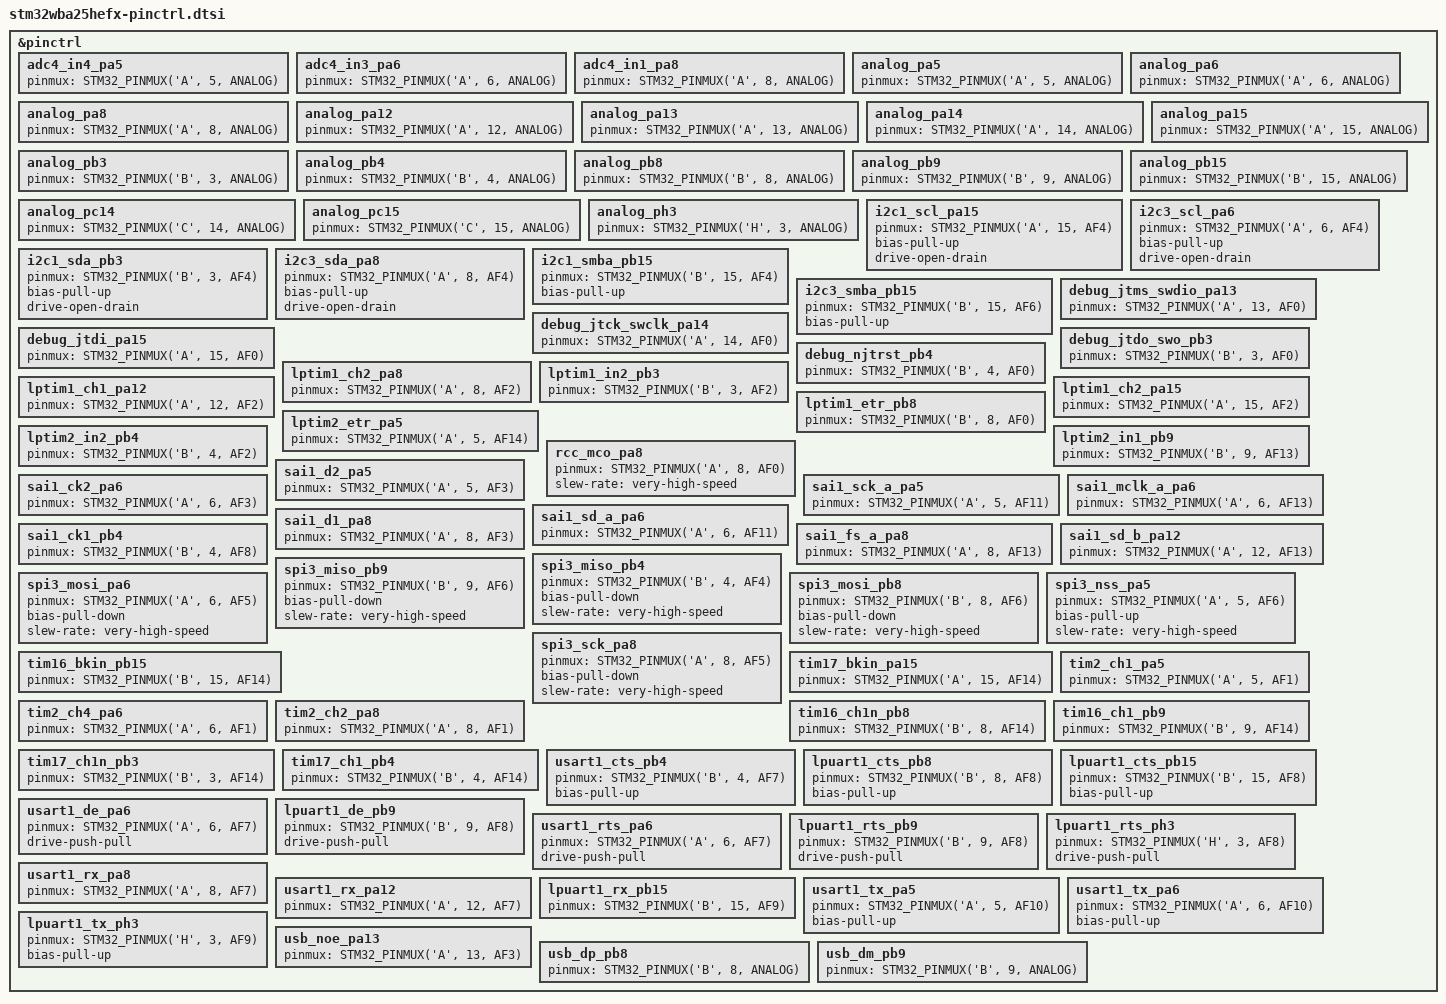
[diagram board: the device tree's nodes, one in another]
/*
 * NOTE: Autogenerated file using genpinctrl.py
 *
 * SPDX-License-Identifier: Apache-2.0
 */

#include <zephyr/dt-bindings/pinctrl/stm32-pinctrl.h>

&pinctrl {

	/* ADC_IN / ADC_INN / ADC_INP */

	/omit-if-no-ref/ adc4_in4_pa5: adc4_in4_pa5 {
		pinmux = <STM32_PINMUX('A', 5, ANALOG)>;
	};

	/omit-if-no-ref/ adc4_in3_pa6: adc4_in3_pa6 {
		pinmux = <STM32_PINMUX('A', 6, ANALOG)>;
	};

	/omit-if-no-ref/ adc4_in1_pa8: adc4_in1_pa8 {
		pinmux = <STM32_PINMUX('A', 8, ANALOG)>;
	};

	/* Analog */

	/omit-if-no-ref/ analog_pa5: analog_pa5 {
		pinmux = <STM32_PINMUX('A', 5, ANALOG)>;
	};

	/omit-if-no-ref/ analog_pa6: analog_pa6 {
		pinmux = <STM32_PINMUX('A', 6, ANALOG)>;
	};

	/omit-if-no-ref/ analog_pa8: analog_pa8 {
		pinmux = <STM32_PINMUX('A', 8, ANALOG)>;
	};

	/omit-if-no-ref/ analog_pa12: analog_pa12 {
		pinmux = <STM32_PINMUX('A', 12, ANALOG)>;
	};

	/omit-if-no-ref/ analog_pa13: analog_pa13 {
		pinmux = <STM32_PINMUX('A', 13, ANALOG)>;
	};

	/omit-if-no-ref/ analog_pa14: analog_pa14 {
		pinmux = <STM32_PINMUX('A', 14, ANALOG)>;
	};

	/omit-if-no-ref/ analog_pa15: analog_pa15 {
		pinmux = <STM32_PINMUX('A', 15, ANALOG)>;
	};

	/omit-if-no-ref/ analog_pb3: analog_pb3 {
		pinmux = <STM32_PINMUX('B', 3, ANALOG)>;
	};

	/omit-if-no-ref/ analog_pb4: analog_pb4 {
		pinmux = <STM32_PINMUX('B', 4, ANALOG)>;
	};

	/omit-if-no-ref/ analog_pb8: analog_pb8 {
		pinmux = <STM32_PINMUX('B', 8, ANALOG)>;
	};

	/omit-if-no-ref/ analog_pb9: analog_pb9 {
		pinmux = <STM32_PINMUX('B', 9, ANALOG)>;
	};

	/omit-if-no-ref/ analog_pb15: analog_pb15 {
		pinmux = <STM32_PINMUX('B', 15, ANALOG)>;
	};

	/omit-if-no-ref/ analog_pc14: analog_pc14 {
		pinmux = <STM32_PINMUX('C', 14, ANALOG)>;
	};

	/omit-if-no-ref/ analog_pc15: analog_pc15 {
		pinmux = <STM32_PINMUX('C', 15, ANALOG)>;
	};

	/omit-if-no-ref/ analog_ph3: analog_ph3 {
		pinmux = <STM32_PINMUX('H', 3, ANALOG)>;
	};

	/* I2C_SCL */

	/omit-if-no-ref/ i2c1_scl_pa15: i2c1_scl_pa15 {
		pinmux = <STM32_PINMUX('A', 15, AF4)>;
		bias-pull-up;
		drive-open-drain;
	};

	/omit-if-no-ref/ i2c3_scl_pa6: i2c3_scl_pa6 {
		pinmux = <STM32_PINMUX('A', 6, AF4)>;
		bias-pull-up;
		drive-open-drain;
	};

	/* I2C_SDA */

	/omit-if-no-ref/ i2c1_sda_pb3: i2c1_sda_pb3 {
		pinmux = <STM32_PINMUX('B', 3, AF4)>;
		bias-pull-up;
		drive-open-drain;
	};

	/omit-if-no-ref/ i2c3_sda_pa8: i2c3_sda_pa8 {
		pinmux = <STM32_PINMUX('A', 8, AF4)>;
		bias-pull-up;
		drive-open-drain;
	};

	/* I2C_SMBA */

	/omit-if-no-ref/ i2c1_smba_pb15: i2c1_smba_pb15 {
		pinmux = <STM32_PINMUX('B', 15, AF4)>;
		bias-pull-up;
	};

	/omit-if-no-ref/ i2c3_smba_pb15: i2c3_smba_pb15 {
		pinmux = <STM32_PINMUX('B', 15, AF6)>;
		bias-pull-up;
	};

	/* JTAG PORT */

	/omit-if-no-ref/ debug_jtms_swdio_pa13: debug_jtms_swdio_pa13 {
		pinmux = <STM32_PINMUX('A', 13, AF0)>;
	};

	/omit-if-no-ref/ debug_jtck_swclk_pa14: debug_jtck_swclk_pa14 {
		pinmux = <STM32_PINMUX('A', 14, AF0)>;
	};

	/omit-if-no-ref/ debug_jtdi_pa15: debug_jtdi_pa15 {
		pinmux = <STM32_PINMUX('A', 15, AF0)>;
	};

	/omit-if-no-ref/ debug_jtdo_swo_pb3: debug_jtdo_swo_pb3 {
		pinmux = <STM32_PINMUX('B', 3, AF0)>;
	};

	/omit-if-no-ref/ debug_njtrst_pb4: debug_njtrst_pb4 {
		pinmux = <STM32_PINMUX('B', 4, AF0)>;
	};

	/* LPTIM */

	/omit-if-no-ref/ lptim1_ch2_pa8: lptim1_ch2_pa8 {
		pinmux = <STM32_PINMUX('A', 8, AF2)>;
	};

	/omit-if-no-ref/ lptim1_ch1_pa12: lptim1_ch1_pa12 {
		pinmux = <STM32_PINMUX('A', 12, AF2)>;
	};

	/omit-if-no-ref/ lptim1_ch2_pa15: lptim1_ch2_pa15 {
		pinmux = <STM32_PINMUX('A', 15, AF2)>;
	};

	/omit-if-no-ref/ lptim1_in2_pb3: lptim1_in2_pb3 {
		pinmux = <STM32_PINMUX('B', 3, AF2)>;
	};

	/omit-if-no-ref/ lptim1_etr_pb8: lptim1_etr_pb8 {
		pinmux = <STM32_PINMUX('B', 8, AF0)>;
	};

	/omit-if-no-ref/ lptim2_etr_pa5: lptim2_etr_pa5 {
		pinmux = <STM32_PINMUX('A', 5, AF14)>;
	};

	/omit-if-no-ref/ lptim2_in2_pb4: lptim2_in2_pb4 {
		pinmux = <STM32_PINMUX('B', 4, AF2)>;
	};

	/omit-if-no-ref/ lptim2_in1_pb9: lptim2_in1_pb9 {
		pinmux = <STM32_PINMUX('B', 9, AF13)>;
	};

	/* RCC_MCO */

	/omit-if-no-ref/ rcc_mco_pa8: rcc_mco_pa8 {
		pinmux = <STM32_PINMUX('A', 8, AF0)>;
		slew-rate = "very-high-speed";
	};

	/* SAI */

	/omit-if-no-ref/ sai1_d2_pa5: sai1_d2_pa5 {
		pinmux = <STM32_PINMUX('A', 5, AF3)>;
	};

	/omit-if-no-ref/ sai1_sck_a_pa5: sai1_sck_a_pa5 {
		pinmux = <STM32_PINMUX('A', 5, AF11)>;
	};

	/omit-if-no-ref/ sai1_ck2_pa6: sai1_ck2_pa6 {
		pinmux = <STM32_PINMUX('A', 6, AF3)>;
	};

	/omit-if-no-ref/ sai1_mclk_a_pa6: sai1_mclk_a_pa6 {
		pinmux = <STM32_PINMUX('A', 6, AF13)>;
	};

	/omit-if-no-ref/ sai1_sd_a_pa6: sai1_sd_a_pa6 {
		pinmux = <STM32_PINMUX('A', 6, AF11)>;
	};

	/omit-if-no-ref/ sai1_d1_pa8: sai1_d1_pa8 {
		pinmux = <STM32_PINMUX('A', 8, AF3)>;
	};

	/omit-if-no-ref/ sai1_fs_a_pa8: sai1_fs_a_pa8 {
		pinmux = <STM32_PINMUX('A', 8, AF13)>;
	};

	/omit-if-no-ref/ sai1_sd_b_pa12: sai1_sd_b_pa12 {
		pinmux = <STM32_PINMUX('A', 12, AF13)>;
	};

	/omit-if-no-ref/ sai1_ck1_pb4: sai1_ck1_pb4 {
		pinmux = <STM32_PINMUX('B', 4, AF8)>;
	};

	/* SPI_MISO */

	/omit-if-no-ref/ spi3_miso_pb4: spi3_miso_pb4 {
		pinmux = <STM32_PINMUX('B', 4, AF4)>;
		bias-pull-down;
		slew-rate = "very-high-speed";
	};

	/omit-if-no-ref/ spi3_miso_pb9: spi3_miso_pb9 {
		pinmux = <STM32_PINMUX('B', 9, AF6)>;
		bias-pull-down;
		slew-rate = "very-high-speed";
	};

	/* SPI_MOSI */

	/omit-if-no-ref/ spi3_mosi_pa6: spi3_mosi_pa6 {
		pinmux = <STM32_PINMUX('A', 6, AF5)>;
		bias-pull-down;
		slew-rate = "very-high-speed";
	};

	/omit-if-no-ref/ spi3_mosi_pb8: spi3_mosi_pb8 {
		pinmux = <STM32_PINMUX('B', 8, AF6)>;
		bias-pull-down;
		slew-rate = "very-high-speed";
	};

	/* SPI_NSS */

	/omit-if-no-ref/ spi3_nss_pa5: spi3_nss_pa5 {
		pinmux = <STM32_PINMUX('A', 5, AF6)>;
		bias-pull-up;
		slew-rate = "very-high-speed";
	};

	/* SPI_SCK */

	/omit-if-no-ref/ spi3_sck_pa8: spi3_sck_pa8 {
		pinmux = <STM32_PINMUX('A', 8, AF5)>;
		bias-pull-down;
		slew-rate = "very-high-speed";
	};

	/* TIM_BKIN */

	/omit-if-no-ref/ tim16_bkin_pb15: tim16_bkin_pb15 {
		pinmux = <STM32_PINMUX('B', 15, AF14)>;
	};

	/omit-if-no-ref/ tim17_bkin_pa15: tim17_bkin_pa15 {
		pinmux = <STM32_PINMUX('A', 15, AF14)>;
	};

	/* TIM_CH / TIM_CHN */

	/omit-if-no-ref/ tim2_ch1_pa5: tim2_ch1_pa5 {
		pinmux = <STM32_PINMUX('A', 5, AF1)>;
	};

	/omit-if-no-ref/ tim2_ch4_pa6: tim2_ch4_pa6 {
		pinmux = <STM32_PINMUX('A', 6, AF1)>;
	};

	/omit-if-no-ref/ tim2_ch2_pa8: tim2_ch2_pa8 {
		pinmux = <STM32_PINMUX('A', 8, AF1)>;
	};

	/omit-if-no-ref/ tim16_ch1n_pb8: tim16_ch1n_pb8 {
		pinmux = <STM32_PINMUX('B', 8, AF14)>;
	};

	/omit-if-no-ref/ tim16_ch1_pb9: tim16_ch1_pb9 {
		pinmux = <STM32_PINMUX('B', 9, AF14)>;
	};

	/omit-if-no-ref/ tim17_ch1n_pb3: tim17_ch1n_pb3 {
		pinmux = <STM32_PINMUX('B', 3, AF14)>;
	};

	/omit-if-no-ref/ tim17_ch1_pb4: tim17_ch1_pb4 {
		pinmux = <STM32_PINMUX('B', 4, AF14)>;
	};

	/* UART_CTS / USART_CTS / LPUART_CTS */

	/omit-if-no-ref/ usart1_cts_pb4: usart1_cts_pb4 {
		pinmux = <STM32_PINMUX('B', 4, AF7)>;
		bias-pull-up;
	};

	/omit-if-no-ref/ lpuart1_cts_pb8: lpuart1_cts_pb8 {
		pinmux = <STM32_PINMUX('B', 8, AF8)>;
		bias-pull-up;
	};

	/omit-if-no-ref/ lpuart1_cts_pb15: lpuart1_cts_pb15 {
		pinmux = <STM32_PINMUX('B', 15, AF8)>;
		bias-pull-up;
	};

	/* UART_DE / USART_DE / LPUART_DE */

	/omit-if-no-ref/ usart1_de_pa6: usart1_de_pa6 {
		pinmux = <STM32_PINMUX('A', 6, AF7)>;
		drive-push-pull;
	};

	/omit-if-no-ref/ lpuart1_de_pb9: lpuart1_de_pb9 {
		pinmux = <STM32_PINMUX('B', 9, AF8)>;
		drive-push-pull;
	};

	/* UART_RTS / USART_RTS / LPUART_RTS */

	/omit-if-no-ref/ usart1_rts_pa6: usart1_rts_pa6 {
		pinmux = <STM32_PINMUX('A', 6, AF7)>;
		drive-push-pull;
	};

	/omit-if-no-ref/ lpuart1_rts_pb9: lpuart1_rts_pb9 {
		pinmux = <STM32_PINMUX('B', 9, AF8)>;
		drive-push-pull;
	};

	/omit-if-no-ref/ lpuart1_rts_ph3: lpuart1_rts_ph3 {
		pinmux = <STM32_PINMUX('H', 3, AF8)>;
		drive-push-pull;
	};

	/* UART_RX / USART_RX / LPUART_RX */

	/omit-if-no-ref/ usart1_rx_pa8: usart1_rx_pa8 {
		pinmux = <STM32_PINMUX('A', 8, AF7)>;
	};

	/omit-if-no-ref/ usart1_rx_pa12: usart1_rx_pa12 {
		pinmux = <STM32_PINMUX('A', 12, AF7)>;
	};

	/omit-if-no-ref/ lpuart1_rx_pb15: lpuart1_rx_pb15 {
		pinmux = <STM32_PINMUX('B', 15, AF9)>;
	};

	/* UART_TX / USART_TX / LPUART_TX */

	/omit-if-no-ref/ usart1_tx_pa5: usart1_tx_pa5 {
		pinmux = <STM32_PINMUX('A', 5, AF10)>;
		bias-pull-up;
	};

	/omit-if-no-ref/ usart1_tx_pa6: usart1_tx_pa6 {
		pinmux = <STM32_PINMUX('A', 6, AF10)>;
		bias-pull-up;
	};

	/omit-if-no-ref/ lpuart1_tx_ph3: lpuart1_tx_ph3 {
		pinmux = <STM32_PINMUX('H', 3, AF9)>;
		bias-pull-up;
	};

	/* USB */

	/omit-if-no-ref/ usb_noe_pa13: usb_noe_pa13 {
		pinmux = <STM32_PINMUX('A', 13, AF3)>;
	};

	/omit-if-no-ref/ usb_dp_pb8: usb_dp_pb8 {
		pinmux = <STM32_PINMUX('B', 8, ANALOG)>;
	};

	/omit-if-no-ref/ usb_dm_pb9: usb_dm_pb9 {
		pinmux = <STM32_PINMUX('B', 9, ANALOG)>;
	};

};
